VERSION "HIPBNYYYYYYYYYYYYYYYYYYYYYYYYYYYYYYYYYYYYY/4/%%%/4/'%**4YYY///"

NS_ :

BS_:

BU_: Diagnostics Sevcon VCU
VAL_TABLE_ TorqueLimitCode 9 "SPEED_LIMIT" 8 "DC_CURRENT_CUTBACK" 7 "DC_VOLTAGE_CUTBACK" 6 "BRIDGE_NOT_ENABLED" 5 "3D_LOOKUP" 4 "USER_LIMITS" 3 "THERMALS" 2 "MOTOR_POWER_MAP" 1 "MAX_PWR" 0 "ID_NONE" ;
VAL_TABLE_ controlword 6 "shutdown" 5 "enable" 3 "energize" ;
VAL_TABLE_ Statusword_values 13 "Fault_Off" 8 "Enabled" 7 "Energised" 4 "Precharge" 2 "Shutdown" 1 "Not_ready_to_switch_on" 0 "None" ;
VAL_TABLE_ Heartbeat 127 "System in pre-operational mode" 5 "System in operational mode" 0 "boot-up" ;
VAL_TABLE_ OperationValues 128 "Return to pre-operational" 1 "Enable operational" ;
VAL_TABLE_ Fault_Codes 18575 "Sensorless Startup" 17868 "Mains Over Voltage" 19585 "HVIL loop Broken" 22401 "CANopen Anon EMCY level 5" 22337 "Invalid power Frame rating" 21711 "IGBT M3 High driver" 21710 "IGBT M3 Low driver" 21709 "IGBT M2 High driver" 21708 "IGBT M2 Low driver" 21707 "IGBT M1 High driver" 21706 "Pump FET s/c, IGBT M1 Low driver" 21705 "MOSFET short circuit checks" 21704 "MOSFET s/c M3 to B-" 21703 "MOSFET s/c M3 to B+" 21702 "MOSFET s/c M2 to B-" 21701 "MOSFET s/c M2 to B+" 21700 "MOSFET s/c M1 to B-" 21699 "MOSFET s/c M1 to B+" 21698 "Power Frame Fault" 21697 "PF Overvoltage" 21570 "Calibration Fault" 21569 "Incompatible hardware version" 21377 "CANopen EMCY level 4" 21318 "Internal Supply Out of Range" 21317 "Sheduler Stack Overflow" 21316 "DSP SPI comms Fault" 21315 "Fault List Overflow" 21314 "OSC watchdog Fault" 21313 "Invalid DSP protocol" 21274 "Ren Protocol" 21273 "Mtr Slave in wrong state" 21272 "SDO Bad Error Number" 21271 "SDO Bad SRC" 21270 "SDO Unknown" 21269 "SDO Send Error" 21268 "SDO Len Error" 21267 "SDO Rec Error" 21266 "SDO Toggle Error" 21265 "SDO State Error" 21264 "SDO Abort Error" 21263 "SDO Timeout Error" 21262 "SDO HDL Error" 21261 "CAN ESTAT set" 21260 "CANopen salve in wrong state" 21259 "CANopen Heartbeat Failed" 21258 "Short PDO Recieved" 21257 "Node guarding Failed" 21256 "CAN Off bus" 21255 "CAN overrun" 21254 "HPTX queue overrun" 21253 "HPRX queue overrun" 21252 "LPTX queue overrun" 21251 "LPRX queue overrun" 21250 "Bootup not recieved" 21249 "CANbus Fault" 21191 "Vcap Over Voltage" 21190 "di/dt Fault" 21189 "Encoder Alignment Severe" 21188 "Motor Overspeed Fault" 21187 "Current Control Fault" 21186 "Motor Over Current" 21185 "Encoder Fault" 20993 "Heatsink Overtemp" 20931 "KL 15/30 too High" 20930 "Capacitor Precharge Failure" 20929 "Power Supply Interrupt" 20872 "AOut short Circuit" 20871 "AOut Under Current" 20870 "AOut Over Temperature" 20869 "AOut Off with FS" 20868 "AOut on without FS" 20867 "Analogue Output Over Current" 20866 "Analogue Input Wire Off" 20865 "Digital Input Wire Off" 20803 "VERLOG" 20802 "Ren Signal" 20801 "BeltLoader Fault" 20738 "Line Contactro Welded" 20737 "Line Contactor O/C" 20609 "Invalid Steer Switches" 20550 "Voltage Auto Config Error" 20549 "Auto Configuration Fault" 20548 "Dynamic Range Error" 20547 "Static Range Error" 20546 "VPDO out of range" 20545 "BAD NVM data" 20353 "CANopen Anon EMCY level 3" 20311 "Motor Stalled" 20310 "Motor in Wrong Direction" 20309 "DSP Parameter Error" 20308 "AutoZero Range Error" 20307 "App Manager SS " 20306 "DSP Comms Error" 20305 "DSP Not Detected" 20304 "New Power Frame Detected" 20303 "Trac APP SS Error" 20302 "DMC SS Error" 20301 "VA SS Error" 20300 "OBD SS Error" 20299 "LCP SS Error" 20298 "LCM SS Error" 20297 "GIO SS Error" 20296 "I/O SS Error" 20295 "DSP Heartbeat Error" 20294 "Sheduler Error" 20293 "Queue Error" 20292 "Timer Failed" 20291 "General DSP Error" 20290 "Out Of Memory" 20289 "Internal Fault" 20226 "EMCY send Failed" 20225 "Unexpected Slave State" 20162 "Pulsing Disabled" 20161 "Can't Establush field current" 20097 "RPDO Timeout (severe)" 19907 "Power Supply Critical" 19779 "Motor Stalled" 19778 "Motor Open Circuit Fault" 19777 "Motor Isolation Fault" 19716 "Circuit Breaker Timeout" 19715 "DC Link Collapsed" 19714 "Circuit Breaker Welded" 19713 "Circuit Breaker Open" 19521 "Too Many Slaves" 19329 "CANopen EMCY level 2" 19203 "IO Data Error" 19202 "Ren Data" 19201 "CANbus Off (drive inhibit)" 19073 "RPDO Timeout (drive inhibit)" 18945 "Cutback" 18882 "Entering Cutback" 18819 "Direction Change" 18818 "E-Brake Wire Off" 18817 "Throttle Fault" 18754 "PST Fault" 18753 "Motor Overspeed" 18574 "Mom Dir Fault" 18573 "Belly Fault" 18572 "Tilt Sensor Fault" 18571 "Illegal Mode Fault" 18570 "Traction inhibit Fault" 18569 "Pothole Fault" 18568 "Raised and Tilted Fault" 18567 "Overload Fault" 18566 "Inch Fault" 18565 "FS1 Recycle Fault" 18564 "Sequence Fault" 18563 "SRO Fault" 18562 "Two Direction Fault" 18561 "Seat Fault" 18369 "Vehicle Service required" 18307 "24V Supply High" 18306 "24V Supplu Low" 18305 "CANopen Anon EMCY level 1" 18242 "Internal Supply Out of range" 18241 "Sheduler Stack Overflow warning" 18177 "CAN Warning" 18118 "Encoder PLL Deactivated Warning" 18117 "Stator Resistance Error" 18116 "Motor Pull-Out Warning" 18115 "Fault Ride through" 18114 "SinCos Tracking warning" 18113 "Encoder Alignment warning" 18051 "RPDO Timeout (warning)" 18050 "Io can't init" 18049 "Unit in Pre-Op" 17924 "Motor too Cold" 17923 "Motor in Thermal Cutback" 17922 "Device too hot" 17921 "Device too cold" 17870 "Vcap Vkey Diff" 17869 "KL15/30 too low" 17867 "Mains Under voltage" 17866 "Motor in high voltage cutback" 17865 "Motor in low voltage cutback" 17864 "Vcap Above rated max" 17863 "Vbat Above rated max" 17862 "Vbat Below rated min" 17861 "High Capacitor Cut" 17860 "High Battery Cut" 17859 "Low Battery Cut" 17858 "BDI Cutout" 17857 "BDI warning" 17802 "Seat warning" 17801 "Analogue Supply warning" 17800 "AOut Short Circuit (warn)" 17799 "AOut Under Current (warn)" 17798 "AOut Over Temperature (warn)" 17797 "AOut Off with Failsafe [warn]" 17796 "AOut Over Current [warn]" 17795 "Safety Case 2" 17794 "Safety Case 1" 17793 "Throttle Fault (Warn)" 17741 "Electrolyte Cutout Level" 17740 "Electrolyte Level Low" 17739 "MOSFET s/c test Waiting" 17738 "Bridge Enable Delayed" 17737 "Pulsed Enable" 17736 "Steer Sensor Warning" 17735 "Tow Mode" 17734 "No Motor Speed Signal" 17733 "Isolation Fault" 17732 "Pump Current Low" 17731 "Hydraulic Fault" 17730 "Low Oil / Device test waiting" 17729 "Fan Fault" 17537 "Handbrake Fault" ;

BO_ 3221225472 VECTOR__INDEPENDENT_SIG_MSG: 0 Vector__XXX
 SG_ New_Signal_76 : 0|8@1+ (1,0) [0|255] "" Vector__XXX
 SG_ New_Signal_73 : 0|8@1+ (1,0) [0|255] "" Vector__XXX
 SG_ Heartbeat : 0|8@1- (1,0) [-128|127] "" Vector__XXX

BO_ 343 Sevcon_unknown_157: 8 Sevcon

BO_ 342 Sevcon_unknown_156: 8 Sevcon

BO_ 128 Sevcon_unknown_80: 0 Sevcon

BO_ 1793 Sevcon_unknown_701: 1 Sevcon

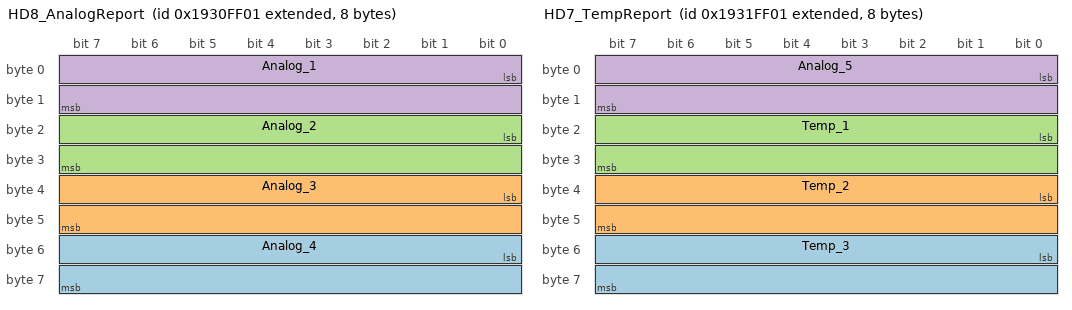
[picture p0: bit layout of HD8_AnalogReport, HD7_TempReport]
BO_ 2570125057 HD8_AnalogReport: 8 Sevcon
 SG_ Analog_4 : 48|16@1+ (4,0) [0|262140] "mV" Vector__XXX
 SG_ Analog_3 : 32|16@1+ (4,0) [0|262140] "mV" Vector__XXX
 SG_ Analog_2 : 16|16@1+ (4,0) [0|262140] "mV" Vector__XXX
 SG_ Analog_1 : 0|16@1+ (4,0) [0|262140] "mV" Vector__XXX

BO_ 2570190593 HD7_TempReport: 8 Sevcon
 SG_ Temp_3 : 48|16@1+ (1,0) [0|65535] "mV" Vector__XXX
 SG_ Temp_2 : 32|16@1+ (1,0) [0|65535] "mV" Vector__XXX
 SG_ Temp_1 : 16|16@1+ (1,0) [0|65535] "mV" Vector__XXX
 SG_ Analog_5 : 0|16@1+ (4,0) [0|262140] "mV" Vector__XXX

BO_ 2568814337 HS5_Encoder_Info_Node_1: 8 Sevcon
 SG_ Encoder_pos : 0|32@1- (1.52588E-005,0) [-32768.0234881024|32768.0234728436] "rotations" Vector__XXX

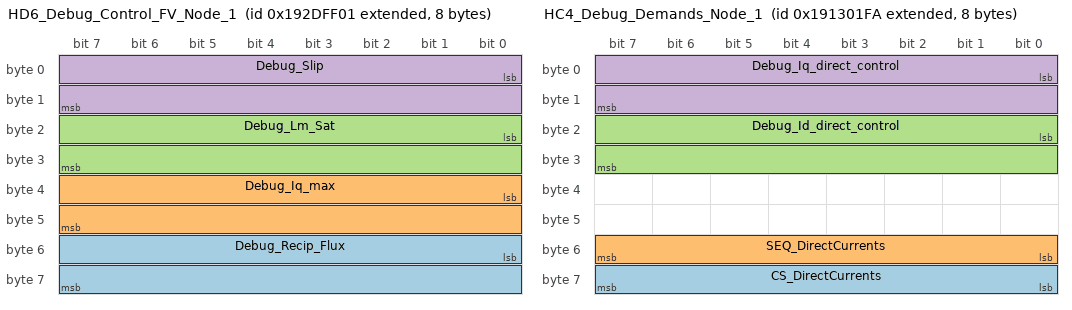
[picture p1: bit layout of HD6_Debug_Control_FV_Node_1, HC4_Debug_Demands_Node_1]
BO_ 2569928449 HD6_Debug_Control_FV_Node_1: 8 Sevcon
 SG_ Debug_Recip_Flux : 48|16@1- (1,0) [-32768|32767] "1/A" Vector__XXX
 SG_ Debug_Iq_max : 32|16@1- (1,0) [-32768|32767] "A" Vector__XXX
 SG_ Debug_Lm_Sat : 16|16@1- (1.52588E-005,0) [-0.5000003584|0.4999850996] "H" Vector__XXX
 SG_ Debug_Slip : 0|16@1- (0.0625,0) [-2048|2047.9375] "rad/s" Vector__XXX

BO_ 2568159738 HC4_Debug_Demands_Node_1: 8 Sevcon
 SG_ CS_DirectCurrents : 56|8@1+ (1,0) [0|255] "" Vector__XXX
 SG_ SEQ_DirectCurrents : 48|8@1+ (1,0) [0|255] "" Vector__XXX
 SG_ Debug_Id_direct_control : 16|16@1- (0.0625,0) [-2048|2047.9375] "A" Vector__XXX
 SG_ Debug_Iq_direct_control : 0|16@1- (0.0625,0) [-2048|2047.9375] "A" Vector__XXX

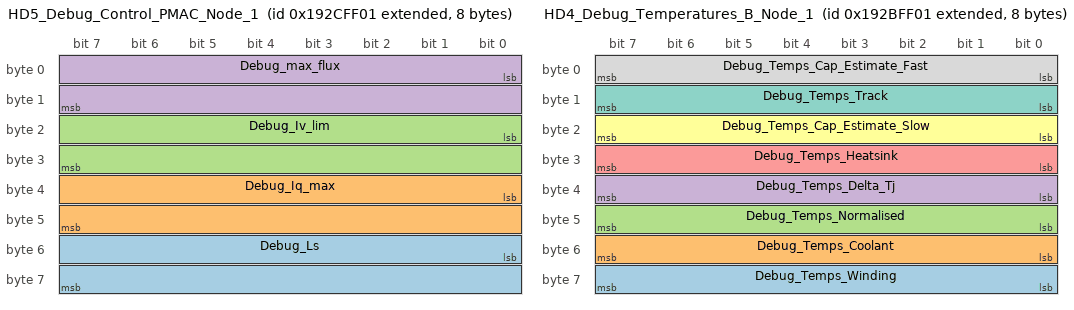
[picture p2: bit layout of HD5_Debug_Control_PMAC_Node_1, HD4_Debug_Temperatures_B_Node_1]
BO_ 2569862913 HD5_Debug_Control_PMAC_Node_1: 8 Sevcon
 SG_ Debug_Ls : 48|16@1- (0.953674,0) [-31249.989632|31249.035958] "uH" Vector__XXX
 SG_ Debug_Iq_max : 32|16@1- (0.0625,0) [-2048|2047.9375] "A" Vector__XXX
 SG_ Debug_Iv_lim : 16|16@1- (0.0625,0) [-2048|2047.9375] "A" Vector__XXX
 SG_ Debug_max_flux : 0|16@1- (0.0625,0) [-2048|2047.9375] "A" Vector__XXX

BO_ 2569797377 HD4_Debug_Temperatures_B_Node_1: 8 Sevcon
 SG_ Debug_Temps_Winding : 56|8@1+ (1,0) [0|255] "degC" Vector__XXX
 SG_ Debug_Temps_Coolant : 48|8@1+ (1,0) [0|255] "degC" Vector__XXX
 SG_ Debug_Temps_Normalised : 40|8@1+ (1,0) [0|255] "degC" Vector__XXX
 SG_ Debug_Temps_Delta_Tj : 32|8@1+ (1,0) [0|255] "degC" Vector__XXX
 SG_ Debug_Temps_Heatsink : 24|8@1+ (1,0) [0|255] "degC" Vector__XXX
 SG_ Debug_Temps_Cap_Estimate_Slow : 16|8@1+ (1,0) [0|255] "degC" Vector__XXX
 SG_ Debug_Temps_Track : 8|8@1+ (1,0) [0|255] "degC" Vector__XXX
 SG_ Debug_Temps_Cap_Estimate_Fast : 0|8@1+ (1,0) [0|255] "degC" Vector__XXX

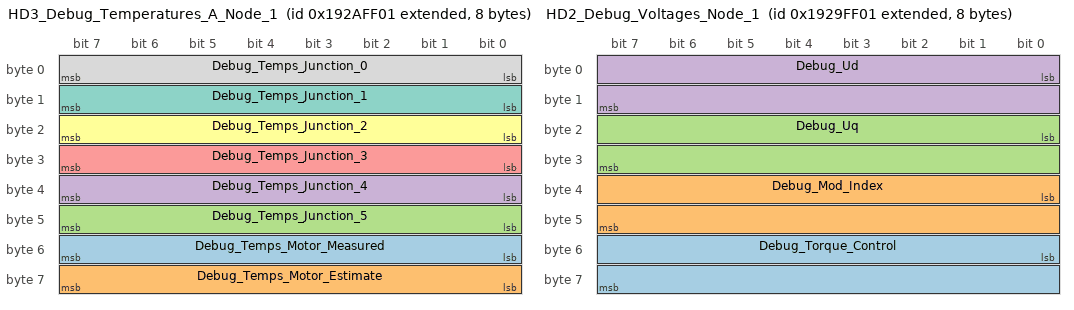
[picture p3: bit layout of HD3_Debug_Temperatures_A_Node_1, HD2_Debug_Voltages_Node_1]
BO_ 2569731841 HD3_Debug_Temperatures_A_Node_1: 8 Sevcon
 SG_ Debug_Temps_Motor_Measured : 48|8@1+ (1,0) [0|255] "degC" Vector__XXX
 SG_ Debug_Temps_Motor_Estimate : 56|8@1+ (1,0) [0|255] "degC" Vector__XXX
 SG_ Debug_Temps_Junction_5 : 40|8@1+ (1,0) [0|255] "degC" Vector__XXX
 SG_ Debug_Temps_Junction_4 : 32|8@1+ (1,0) [0|255] "degC" Vector__XXX
 SG_ Debug_Temps_Junction_3 : 24|8@1+ (1,0) [0|255] "degC" Vector__XXX
 SG_ Debug_Temps_Junction_2 : 16|8@1+ (1,0) [0|255] "degC" Vector__XXX
 SG_ Debug_Temps_Junction_1 : 8|8@1+ (1,0) [0|255] "degC" Vector__XXX
 SG_ Debug_Temps_Junction_0 : 0|8@1+ (1,0) [0|255] "degC" Vector__XXX

BO_ 2569666305 HD2_Debug_Voltages_Node_1: 8 Sevcon
 SG_ Debug_Torque_Control : 48|16@1- (0.0625,0) [-2048|2047.9375] "Nm" Vector__XXX
 SG_ Debug_Mod_Index : 32|16@1+ (0.392157,0) [0|25700.008995] "%" Vector__XXX
 SG_ Debug_Uq : 16|16@1- (0.0625,0) [-2048|2047.9375] "V" Vector__XXX
 SG_ Debug_Ud : 0|16@1- (0.0625,0) [-2048|2047.9375] "V" Vector__XXX

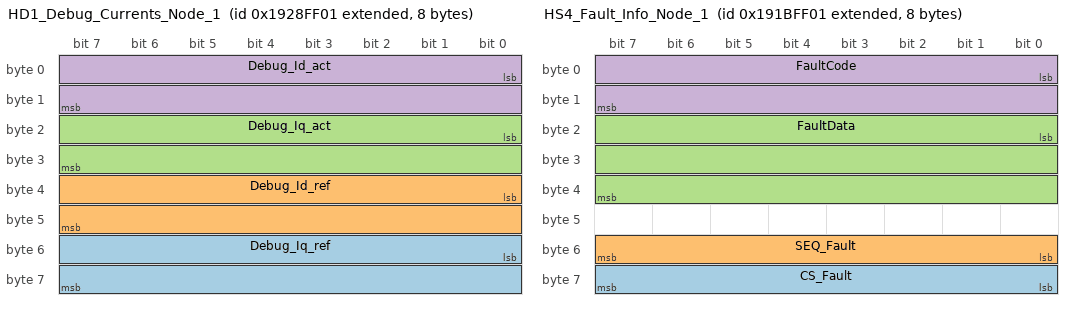
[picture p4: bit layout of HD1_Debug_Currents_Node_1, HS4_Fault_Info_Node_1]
BO_ 2569600769 HD1_Debug_Currents_Node_1: 8 Sevcon
 SG_ Debug_Iq_ref : 48|16@1- (0.0625,0) [-2048|2047.9375] "A" Vector__XXX
 SG_ Debug_Id_ref : 32|16@1- (0.0625,0) [-2048|2047.9375] "A" Vector__XXX
 SG_ Debug_Iq_act : 16|16@1- (0.0625,0) [-2048|2047.9375] "A" Vector__XXX
 SG_ Debug_Id_act : 0|16@1- (0.0625,0) [-2048|2047.9375] "A" Vector__XXX

BO_ 2568748801 HS4_Fault_Info_Node_1: 8 Sevcon
 SG_ CS_Fault : 56|8@1+ (1,0) [0|255] ""  VCU
 SG_ SEQ_Fault : 48|8@1+ (1,0) [0|255] ""  VCU
 SG_ FaultData : 16|24@1- (1,0) [-8388608|8388607] ""  VCU
 SG_ FaultCode : 0|16@1- (1,0) [-32768|32767] ""  VCU

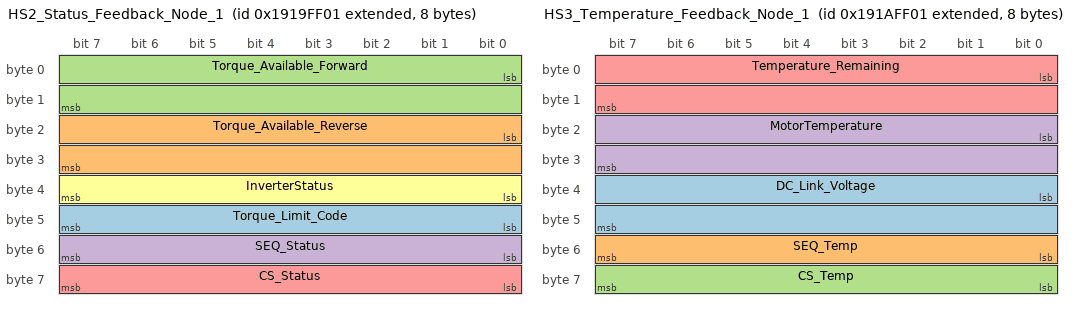
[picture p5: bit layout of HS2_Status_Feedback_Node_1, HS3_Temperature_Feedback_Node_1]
BO_ 2568617729 HS2_Status_Feedback_Node_1: 8 Sevcon
 SG_ Torque_Limit_Code : 40|8@1+ (1,0) [0|255] "" Vector__XXX
 SG_ Torque_Available_Reverse : 16|16@1- (0.0625,0) [-2048|2047.9375] "Nm"  VCU
 SG_ Torque_Available_Forward : 0|16@1- (0.0625,0) [-2048|2047.9375] "Nm"  VCU
 SG_ SEQ_Status : 48|8@1+ (1,0) [0|255] ""  VCU
 SG_ CS_Status : 56|8@1+ (1,0) [0|255] ""  VCU
 SG_ InverterStatus : 32|8@1+ (1,0) [0|255] "-"  VCU

BO_ 2568683265 HS3_Temperature_Feedback_Node_1: 8 Sevcon
 SG_ DC_Link_Voltage : 32|16@1- (0.0625,0) [-2048|2047.9375] "V"  VCU
 SG_ SEQ_Temp : 48|8@1+ (1,0) [0|255] ""  VCU
 SG_ CS_Temp : 56|8@1+ (1,0) [0|255] ""  VCU
 SG_ MotorTemperature : 16|16@1- (1,0) [-32768|32767] "C"  VCU
 SG_ Temperature_Remaining : 0|16@1- (1,0) [-40|100] "C"  VCU

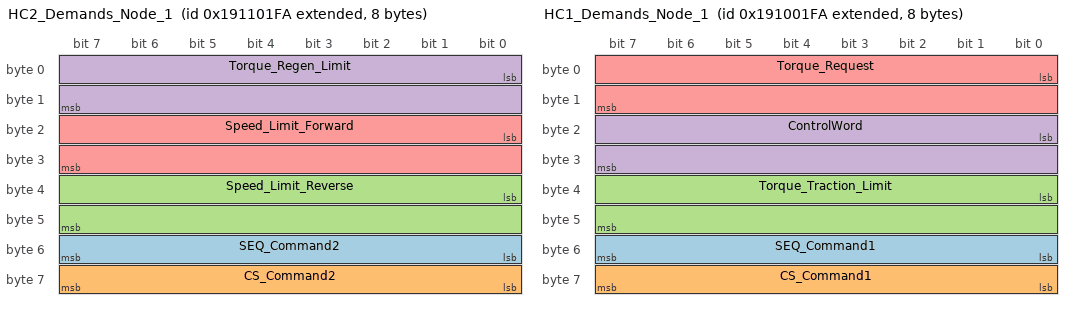
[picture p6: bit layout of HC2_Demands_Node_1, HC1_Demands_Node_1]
BO_ 2568028666 HC2_Demands_Node_1: 8 VCU
 SG_ SEQ_Command2 : 48|8@1+ (1,0) [0|255] ""  Sevcon
 SG_ CS_Command2 : 56|8@1+ (1,0) [0|255] ""  Sevcon
 SG_ Speed_Limit_Reverse : 32|16@1- (1,0) [-32768|32767] "RPM"  Sevcon
 SG_ Torque_Regen_Limit : 0|16@1- (0.0625,0) [-2048|2047.9375] "Nm"  Sevcon
 SG_ Speed_Limit_Forward : 16|16@1- (1,0) [-32768|32767] "RPM"  Sevcon

BO_ 2567963130 HC1_Demands_Node_1: 8 VCU
 SG_ SEQ_Command1 : 48|8@1+ (1,0) [0|255] ""  Sevcon
 SG_ CS_Command1 : 56|8@1+ (1,0) [0|255] ""  Sevcon
 SG_ Torque_Traction_Limit : 32|16@1- (0.0625,0) [-2048|2047.9375] "Nm"  Sevcon
 SG_ ControlWord : 16|16@1- (1,0) [-32768|32767] ""  Sevcon
 SG_ Torque_Request : 0|16@1- (0.0625,0) [-2048|2047.9375] "Nm"  Sevcon

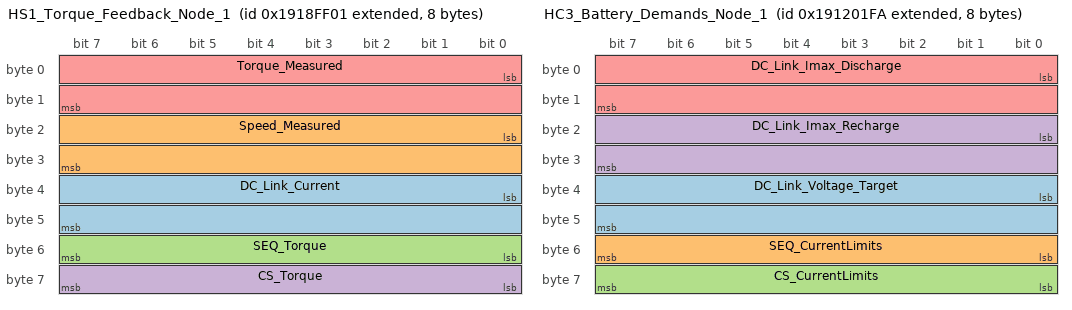
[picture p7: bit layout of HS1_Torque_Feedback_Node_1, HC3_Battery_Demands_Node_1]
BO_ 2568552193 HS1_Torque_Feedback_Node_1: 8 Sevcon
 SG_ DC_Link_Current : 32|16@1- (1,0) [-32768|32767] "A"  VCU
 SG_ Speed_Measured : 16|16@1- (1,0) [-32768|32767] "RPM"  VCU
 SG_ SEQ_Torque : 48|8@1+ (1,0) [0|255] ""  VCU
 SG_ CS_Torque : 56|8@1+ (1,0) [0|255] ""  VCU
 SG_ Torque_Measured : 0|16@1- (0.0625,0) [-2048|2047.9375] "Nm"  VCU

BO_ 2568094202 HC3_Battery_Demands_Node_1: 8 VCU
 SG_ DC_Link_Voltage_Target : 32|16@1- (0.0625,0) [-2048|2047.9375] "V" Vector__XXX
 SG_ SEQ_CurrentLimits : 48|8@1+ (1,0) [0|255] ""  Sevcon
 SG_ CS_CurrentLimits : 56|8@1+ (1,0) [0|255] ""  Sevcon
 SG_ DC_Link_Imax_Recharge : 16|16@1- (1,0) [-32768|32767] "A"  Sevcon
 SG_ DC_Link_Imax_Discharge : 0|16@1- (1,0) [-32768|32767] "A"  Sevcon

CM_ BU_ Sevcon "Torque generating inverter";
CM_ BU_ VCU "Central vehicle control unit, responsible for generating torque demands for the inverter";
CM_ BO_ 3221225472 "This is a message for not used signals, created by Vector CANdb++ DBC OLE DB Provider.";
CM_ SG_ 2569666305 Debug_Torque_Control "Torque that is to be used as the control value for caluclating current references";
CM_ SG_ 2568748801 CS_Fault "Command1 message checksum";
CM_ SG_ 2568748801 SEQ_Fault "Command1 message sequence counter";
CM_ BO_ 2568617729 "To command the anciliary switch";
CM_ SG_ 2568617729 Torque_Available_Reverse "Torque available calculated by inverter";
CM_ SG_ 2568617729 Torque_Available_Forward "Torque available calculated by inverter";
CM_ SG_ 2568617729 SEQ_Status "Status message sequence counter";
CM_ SG_ 2568617729 CS_Status "Status message checksum";
CM_ SG_ 2568617729 InverterStatus "Inverter status (TBD)";
CM_ BO_ 2568683265 "To command the anciliary switch";
CM_ SG_ 2568683265 SEQ_Temp "Temperature message sequence counter";
CM_ SG_ 2568683265 CS_Temp "Temperature message checksum";
CM_ SG_ 2568683265 MotorTemperature "Measured motor temperature";
CM_ SG_ 2568683265 Temperature_Remaining "Inverter module temperature";
CM_ BO_ 2568028666 "Active derates and values";
CM_ SG_ 2568028666 SEQ_Command2 "Command2 message sequence counter";
CM_ SG_ 2568028666 CS_Command2 "Command2 message checksum";
CM_ SG_ 2568028666 Speed_Limit_Reverse "Maximum reverse speed of motor";
CM_ SG_ 2568028666 Torque_Regen_Limit "Torque limit specified by VCM";
CM_ SG_ 2568028666 Speed_Limit_Forward "Maximum forward speed of motor";
CM_ BO_ 2567963130 "Active derates and values";
CM_ SG_ 2567963130 SEQ_Command1 "Command1 message sequence counter";
CM_ SG_ 2567963130 CS_Command1 "Command1 message checksum";
CM_ SG_ 2567963130 Torque_Traction_Limit "Max torque calculated by VCM";
CM_ SG_ 2567963130 ControlWord "Control word that sets inverter mode of operation";
CM_ SG_ 2567963130 Torque_Request "Motor torque requested by VCM";
CM_ BO_ 2568552193 "To command the anciliary switch";
CM_ SG_ 2568552193 DC_Link_Current "Net current flow measured by the inverter";
CM_ SG_ 2568552193 Speed_Measured "Measured motor speed by inverter";
CM_ SG_ 2568552193 SEQ_Torque "Torque message sequence counter";
CM_ SG_ 2568552193 CS_Torque "Torque message checksum";
CM_ SG_ 2568552193 Torque_Measured "Torque calculated by DSP in inverter";
CM_ BO_ 2568094202 "Response back to BMS";
CM_ SG_ 2568094202 DC_Link_Voltage_Target "Min motor current calculated by VCM (regen)";
CM_ SG_ 2568094202 SEQ_CurrentLimits "Current limits message sequence counter";
CM_ SG_ 2568094202 CS_CurrentLimits "Current limits message checksum";
CM_ SG_ 2568094202 DC_Link_Imax_Recharge "Min motor current calculated by VCM (regen)";
CM_ SG_ 2568094202 DC_Link_Imax_Discharge "Max motor current calculated by VCM (traction)";
BA_DEF_ BO_  "GenMsgSendType" ENUM  "Cyclic","not_used","not_used","not_used","not_used","Cyclic","not_used","IfActive";
BA_DEF_ BO_  "GenMsgCycleTime" INT 0 0;
BA_DEF_ BO_  "VFrameFormat" ENUM  "StandardCAN","ExtendedCAN","reserved","J1939PG";
BA_DEF_  "BusType" STRING ;
BA_DEF_DEF_  "GenMsgSendType" "not_used";
BA_DEF_DEF_  "GenMsgCycleTime" 0;
BA_DEF_DEF_  "VFrameFormat" "J1939PG";
BA_DEF_DEF_  "BusType" "";
BA_ "BusType" "CAN";
BA_ "GenMsgSendType" BO_ 343 7;
BA_ "VFrameFormat" BO_ 343 0;
BA_ "GenMsgSendType" BO_ 342 7;
BA_ "VFrameFormat" BO_ 342 0;
BA_ "GenMsgSendType" BO_ 128 0;
BA_ "GenMsgCycleTime" BO_ 128 100;
BA_ "VFrameFormat" BO_ 128 0;
BA_ "GenMsgSendType" BO_ 1793 0;
BA_ "GenMsgCycleTime" BO_ 1793 100;
BA_ "VFrameFormat" BO_ 1793 0;
BA_ "VFrameFormat" BO_ 2570125057 1;
BA_ "GenMsgCycleTime" BO_ 2570125057 500;
BA_ "GenMsgSendType" BO_ 2570125057 0;
BA_ "VFrameFormat" BO_ 2570190593 1;
BA_ "GenMsgCycleTime" BO_ 2570190593 500;
BA_ "GenMsgSendType" BO_ 2570190593 0;
BA_ "VFrameFormat" BO_ 2568814337 1;
BA_ "GenMsgCycleTime" BO_ 2568814337 48;
BA_ "GenMsgSendType" BO_ 2568814337 0;
BA_ "VFrameFormat" BO_ 2569928449 1;
BA_ "VFrameFormat" BO_ 2568159738 1;
BA_ "GenMsgCycleTime" BO_ 2569862913 1000;
BA_ "GenMsgSendType" BO_ 2569862913 0;
BA_ "VFrameFormat" BO_ 2569862913 1;
BA_ "GenMsgCycleTime" BO_ 2569797377 1000;
BA_ "GenMsgSendType" BO_ 2569797377 0;
BA_ "VFrameFormat" BO_ 2569797377 1;
BA_ "GenMsgCycleTime" BO_ 2569731841 1000;
BA_ "GenMsgSendType" BO_ 2569731841 0;
BA_ "VFrameFormat" BO_ 2569731841 1;
BA_ "GenMsgCycleTime" BO_ 2569666305 1000;
BA_ "GenMsgSendType" BO_ 2569666305 0;
BA_ "VFrameFormat" BO_ 2569666305 1;
BA_ "GenMsgSendType" BO_ 2569600769 0;
BA_ "GenMsgCycleTime" BO_ 2569600769 1000;
BA_ "VFrameFormat" BO_ 2569600769 1;
BA_ "GenMsgCycleTime" BO_ 2568748801 1000;
BA_ "GenMsgSendType" BO_ 2568748801 0;
BA_ "VFrameFormat" BO_ 2568748801 1;
BA_ "GenMsgCycleTime" BO_ 2568617729 48;
BA_ "GenMsgSendType" BO_ 2568617729 0;
BA_ "VFrameFormat" BO_ 2568617729 1;
BA_ "GenMsgCycleTime" BO_ 2568683265 48;
BA_ "GenMsgSendType" BO_ 2568683265 0;
BA_ "VFrameFormat" BO_ 2568683265 1;
BA_ "GenMsgCycleTime" BO_ 2568028666 25;
BA_ "GenMsgSendType" BO_ 2568028666 0;
BA_ "VFrameFormat" BO_ 2568028666 1;
BA_ "GenMsgCycleTime" BO_ 2567963130 25;
BA_ "GenMsgSendType" BO_ 2567963130 0;
BA_ "VFrameFormat" BO_ 2567963130 1;
BA_ "GenMsgCycleTime" BO_ 2568552193 48;
BA_ "GenMsgSendType" BO_ 2568552193 0;
BA_ "VFrameFormat" BO_ 2568552193 1;
BA_ "GenMsgCycleTime" BO_ 2568094202 25;
BA_ "GenMsgSendType" BO_ 2568094202 0;
BA_ "VFrameFormat" BO_ 2568094202 1;
VAL_ 3221225472 Heartbeat 127 "System in pre-operational mode" 5 "System in operational mode" 0 "boot-up" ;
VAL_ 2568748801 FaultCode 0 "No Fault" 18575 "Sensorless Startup" 17868 "Mains Over Voltage" 19585 "HVIL loop Broken" 22401 "CANopen Anon EMCY level 5" 22337 "Invalid power Frame rating" 21711 "IGBT M3 High driver" 21710 "IGBT M3 Low driver" 21709 "IGBT M2 High driver" 21708 "IGBT M2 Low driver" 21707 "IGBT M1 High driver" 21706 "Pump FET s/c, IGBT M1 Low driver" 21705 "MOSFET short circuit checks" 21704 "MOSFET s/c M3 to B-" 21703 "MOSFET s/c M3 to B+" 21702 "MOSFET s/c M2 to B-" 21701 "MOSFET s/c M2 to B+" 21700 "MOSFET s/c M1 to B-" 21699 "MOSFET s/c M1 to B+" 21698 "Power Frame Fault" 21697 "PF Overvoltage" 21570 "Calibration Fault" 21569 "Incompatible hardware version" 21377 "CANopen EMCY level 4" 21318 "Internal Supply Out of Range" 21317 "Sheduler Stack Overflow" 21316 "DSP SPI comms Fault" 21315 "Fault List Overflow" 21314 "OSC watchdog Fault" 21313 "Invalid DSP protocol" 21274 "Ren Protocol" 21273 "Mtr Slave in wrong state" 21272 "SDO Bad Error Number" 21271 "SDO Bad SRC" 21270 "SDO Unknown" 21269 "SDO Send Error" 21268 "SDO Len Error" 21267 "SDO Rec Error" 21266 "SDO Toggle Error" 21265 "SDO State Error" 21264 "SDO Abort Error" 21263 "SDO Timeout Error" 21262 "SDO HDL Error" 21261 "CAN ESTAT set" 21260 "CANopen salve in wrong state" 21259 "CANopen Heartbeat Failed" 21258 "Short PDO Recieved" 21257 "Node guarding Failed" 21256 "CAN Off bus" 21255 "CAN overrun" 21254 "HPTX queue overrun" 21253 "HPRX queue overrun" 21252 "LPTX queue overrun" 21251 "LPRX queue overrun" 21250 "Bootup not recieved" 21249 "CANbus Fault" 21191 "Vcap Over Voltage" 21190 "di/dt Fault" 21189 "Encoder Alignment Severe" 21188 "Motor Overspeed Fault" 21187 "Current Control Fault" 21186 "Motor Over Current" 21185 "Encoder Fault" 20993 "Heatsink Overtemp" 20931 "KL 15/30 too High" 20930 "Capacitor Precharge Failure" 20929 "Power Supply Interrupt" 20872 "AOut short Circuit" 20871 "AOut Under Current" 20870 "AOut Over Temperature" 20869 "AOut Off with FS" 20868 "AOut on without FS" 20867 "Analogue Output Over Current" 20866 "Analogue Input Wire Off" 20865 "Digital Input Wire Off" 20803 "VERLOG" 20802 "Ren Signal" 20801 "BeltLoader Fault" 20738 "Line Contactro Welded" 20737 "Line Contactor O/C" 20609 "Invalid Steer Switches" 20550 "Voltage Auto Config Error" 20549 "Auto Configuration Fault" 20548 "Dynamic Range Error" 20547 "Static Range Error" 20546 "VPDO out of range" 20545 "BAD NVM data" 20353 "CANopen Anon EMCY level 3" 20311 "Motor Stalled" 20310 "Motor in Wrong Direction" 20309 "DSP Parameter Error" 20308 "AutoZero Range Error" 20307 "App Manager SS " 20306 "DSP Comms Error" 20305 "DSP Not Detected" 20304 "New Power Frame Detected" 20303 "Trac APP SS Error" 20302 "DMC SS Error" 20301 "VA SS Error" 20300 "OBD SS Error" 20299 "LCP SS Error" 20298 "LCM SS Error" 20297 "GIO SS Error" 20296 "I/O SS Error" 20295 "DSP Heartbeat Error" 20294 "Sheduler Error" 20293 "Queue Error" 20292 "Timer Failed" 20291 "General DSP Error" 20290 "Out Of Memory" 20289 "Internal Fault" 20226 "EMCY send Failed" 20225 "Unexpected Slave State" 20162 "Pulsing Disabled" 20161 "Can't Establush field current" 20097 "RPDO Timeout (severe)" 19907 "Power Supply Critical" 19779 "Motor Stalled" 19778 "Motor Open Circuit Fault" 19777 "Motor Isolation Fault" 19716 "Circuit Breaker Timeout" 19715 "DC Link Collapsed" 19714 "Circuit Breaker Welded" 19713 "Circuit Breaker Open" 19521 "Too Many Slaves" 19329 "CANopen EMCY level 2" 19203 "IO Data Error" 19202 "Ren Data" 19201 "CANbus Off (drive inhibit)" 19073 "RPDO Timeout (drive inhibit)" 18945 "Cutback" 18882 "Entering Cutback" 18819 "Direction Change" 18818 "E-Brake Wire Off" 18817 "Throttle Fault" 18754 "PST Fault" 18753 "Motor Overspeed" 18574 "Mom Dir Fault" 18573 "Belly Fault" 18572 "Tilt Sensor Fault" 18571 "Illegal Mode Fault" 18570 "Traction inhibit Fault" 18569 "Pothole Fault" 18568 "Raised and Tilted Fault" 18567 "Overload Fault" 18566 "Inch Fault" 18565 "FS1 Recycle Fault" 18564 "Sequence Fault" 18563 "SRO Fault" 18562 "Two Direction Fault" 18561 "Seat Fault" 18369 "Vehicle Service required" 18307 "24V Supply High" 18306 "24V Supplu Low" 18305 "CANopen Anon EMCY level 1" 18242 "Internal Supply Out of range" 18241 "Sheduler Stack Overflow warning" 18177 "CAN Warning" 18118 "Encoder PLL Deactivated Warning" 18117 "Stator Resistance Error" 18116 "Motor Pull-Out Warning" 18115 "Fault Ride through" 18114 "SinCos Tracking warning" 18113 "Encoder Alignment warning" 18051 "RPDO Timeout (warning)" 18050 "Io can't init" 18049 "Unit in Pre-Op" 17924 "Motor too Cold" 17923 "Motor in Thermal Cutback" 17922 "Device too hot" 17921 "Device too cold" 17870 "Vcap Vkey Diff" 17869 "KL15/30 too low" 17867 "Mains Under voltage" 17866 "Motor in high voltage cutback" 17865 "Motor in low voltage cutback" 17864 "Vcap Above rated max" 17863 "Vbat Above rated max" 17862 "Vbat Below rated min" 17861 "High Capacitor Cut" 17860 "High Battery Cut" 17859 "Low Battery Cut" 17858 "BDI Cutout" 17857 "BDI warning" 17802 "Seat warning" 17801 "Analogue Supply warning" 17800 "AOut Short Circuit (warn)" 17799 "AOut Under Current (warn)" 17798 "AOut Over Temperature (warn)" 17797 "AOut Off with Failsafe [warn]" 17796 "AOut Over Current [warn]" 17795 "Safety Case 2" 17794 "Safety Case 1" 17793 "Throttle Fault (Warn)" 17741 "Electrolyte Cutout Level" 17740 "Electrolyte Level Low" 17739 "MOSFET s/c test Waiting" 17738 "Bridge Enable Delayed" 17737 "Pulsed Enable" 17736 "Steer Sensor Warning" 17735 "Tow Mode" 17734 "No Motor Speed Signal" 17733 "Isolation Fault" 17732 "Pump Current Low" 17731 "Hydraulic Fault" 17730 "Low Oil / Device test waiting" 17729 "Fan Fault" 17537 "Handbrake Fault" ;
VAL_ 2568617729 Torque_Limit_Code 9 "SPEED_LIMIT" 8 "DC_CURRENT_CUTBACK" 7 "DC_VOLTAGE_CUTBACK" 6 "BRIDGE_NOT_ENABLED" 5 "3D_LOOKUP" 4 "USER_LIMITS" 3 "THERMALS" 2 "MOTOR_POWER_MAP" 1 "MAX_PWR" 0 "ID_NONE" ;
VAL_ 2568617729 InverterStatus 13 "Fault_Off" 8 "Enabled" 7 "Energised" 4 "Precharge" 2 "Shutdown" 1 "Not_ready_to_switch_on" 0 "None" ;
VAL_ 2567963130 ControlWord 6 "shutdown" 5 "enable" 3 "energize" ;
